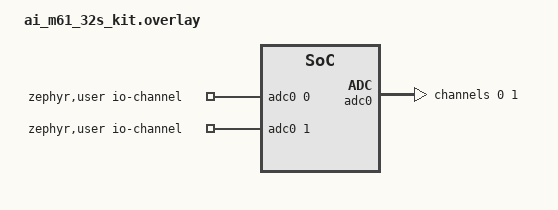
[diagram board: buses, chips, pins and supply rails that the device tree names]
/*
 * Copyright (c) 2024-2026 MASSDRIVER EI (massdriver.space)
 *
 * SPDX-License-Identifier: Apache-2.0
 */

/ {
	zephyr,user {
		io-channels = <&adc0 0>, <&adc0 1>;
	};
};

&pinctrl {
	adc0_default: adc0_default {
		group1 {
			pinmux = <GPIO14_ADC_CH4>,
				 <GPIO13_ADC_CH5>;
		};
	};
};

&adc0 {
	status = "okay";

	pinctrl-0 = <&adc0_default>;
	pinctrl-names = "default";

	channel@0 {
		reg = <0>;
		zephyr,gain = "ADC_GAIN_1";
		zephyr,reference = "ADC_REF_INTERNAL";
		zephyr,acquisition-time = <ADC_ACQ_TIME_DEFAULT>;
		zephyr,resolution = <16>;
		zephyr,input-positive = <4>;
	};

	channel@1 {
		reg = <1>;
		zephyr,gain = "ADC_GAIN_1";
		zephyr,reference = "ADC_REF_INTERNAL";
		zephyr,acquisition-time = <ADC_ACQ_TIME_DEFAULT>;
		zephyr,resolution = <16>;
		zephyr,input-positive = <5>;
	};
};
